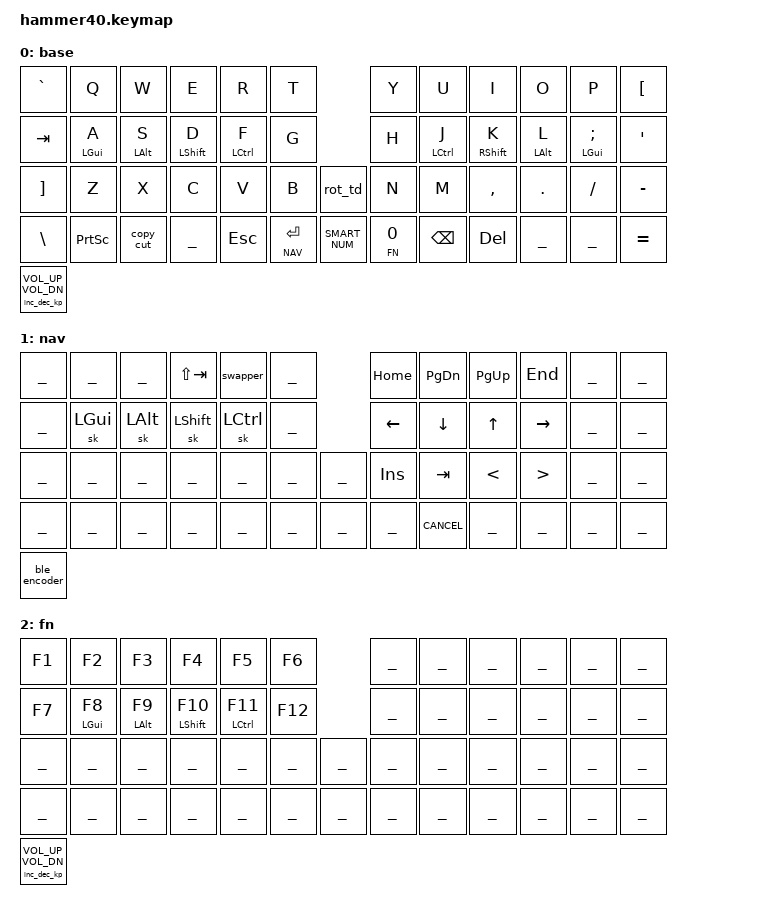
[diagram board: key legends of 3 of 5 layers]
/*
 * Copyright (c) 2020 The ZMK Contributors
 *
 * SPDX-License-Identifier: MIT
 */

#include <behaviors.dtsi>
#include <dt-bindings/zmk/keys.h>
#include <dt-bindings/zmk/bt.h>
#include <dt-bindings/zmk/outputs.h>

#include "hammer40_keylabels.h"
#include "zmk-helpers/helper.h"
#include "zmk-helpers/unicode-chars/currency.dtsi"

/* Layers */
#define DEF 0
#define NAV 1
#define FN 2
#define NUM 3
#define SYS 4

#include "mouse.dtsi"
#include "combos.dtsi"
#include "behave.dtsi"

/* Custom behaviors */

/ {
    behaviors {
        ble_encoder: ble_encoder {
            compatible = "zmk,behavior-sensor-rotate";
            #sensor-binding-cells = <0>;
            bindings = <&bt BT_NXT>, <&bt BT_PRV>;
        };
    };
};

// tap: play/pause | double-tap: media next | triple-tap: media previous
ZMK_TAP_DANCE(rot_td,
    tapping-term-ms = <250>;
    bindings = <&kp C_PP>, <&kp C_NEXT>, <&kp C_PREV>;
)


/* Keymap */

ZMK_CONDITIONAL_LAYER(sys, FN NUM, SYS)  // FN + NUM --> SYS

ZMK_LAYER(base,
//╭─────────────┬─────────────┬─────────────┬─────────────┬─────────────┬─────────────╮             ╭─────────────┬─────────────┬─────────────┬─────────────┬─────────────┬─────────────╮
    &kp GRAVE     &kp Q         &kp W         &kp E         &kp R         &kp T                       &kp Y         &kp U         &kp I         &kp O         &kp P           &kp LBKT
//├─────────────┼─────────────┼─────────────┼─────────────┼─────────────┼─────────────┤             ├─────────────┼─────────────┼─────────────┼─────────────┼─────────────┼─────────────┤
    &kp TAB       &hml LGUI A   &hml LALT S   &hml LSHFT D  &hml LCTRL F  &kp G                       &kp H         &hmr LCTRL J  &hmr RSHFT K  &hmr LALT L   &hmr LGUI SEMI  &kp APOS
//├─────────────┼─────────────┼─────────────┼─────────────┼─────────────┼─────────────┤ ╭─────────╮ ├─────────────┼─────────────┼─────────────┼─────────────┼─────────────┼─────────────┤
    &kp RBKT      &kp Z         &kp X         &kp C         &kp V         &kp B          &rot_td      &kp N         &kp M         &kp COMMA     &kp DOT       &kp FSLH        &kp MINUS
//├─────────────┼─────────────┼─────────────┼─────────────┼─────────────┼─────────────┼─────────────┼─────────────┼─────────────┼─────────────┼─────────────┼─────────────┼─────────────┤
    &kp BSLH      &kp PSCRN     &copy_cut     ___           &kp ESC       &lt NAV ENTER  SMART_NUM    &lt_spc FN 0  &kp BSPC      &kp DEL       ___           ___             &kp EQUAL
//╰─────────────┴─────────────┴─────────────┴─────────────┴─────────────┴─────────────┴─────────────┴─────────────┴─────────────┴─────────────┴─────────────┴─────────────┴─────────────╯ 
    , &inc_dec_kp C_VOL_UP C_VOL_DN
)

ZMK_LAYER(nav,
//╭─────────────┬─────────────┬─────────────┬─────────────┬─────────────┬─────────────╮             ╭─────────────┬─────────────┬─────────────┬─────────────┬─────────────┬─────────────╮
    ___           ___           ___           &kp LS(TAB)   &swapper      ___                         &kp HOME      &kp PG_DN     &kp PG_UP     &kp END       ___           ___
//├─────────────┼─────────────┼─────────────┼─────────────┼─────────────┼─────────────┤             ├─────────────┼─────────────┼─────────────┼─────────────┼─────────────┼─────────────┤
    ___           &sk LGUI      &sk LALT      &sk LSHFT     &sk LCTRL     ___                         &kp LEFT      &kp DOWN      &kp UP        &kp RIGHT     ___           ___
//├─────────────┼─────────────┼─────────────┼─────────────┼─────────────┼─────────────┤ ╭─────────╮ ├─────────────┼─────────────┼─────────────┼─────────────┼─────────────┼─────────────┤
    ___           ___           ___           ___           ___           ___               ___       &kp INS       &kp TAB       &kp LT        &kp GT        ___           ___
//├─────────────┼─────────────┼─────────────┼─────────────┼─────────────┼─────────────┼─────────────┼─────────────┼─────────────┼─────────────┼─────────────┼─────────────┼─────────────┤
    ___           ___           ___           ___           ___           ___               ___       ___           CANCEL        ___           ___           ___           ___
//╰─────────────┴─────────────┴─────────────┴─────────────┴─────────────┴─────────────┴─────────────┴─────────────┴─────────────┴─────────────┴─────────────┴─────────────┴─────────────╯ 
    , &ble_encoder
)

ZMK_LAYER(fn,
//╭─────────────┬─────────────┬─────────────┬─────────────┬─────────────┬─────────────╮             ╭─────────────┬─────────────┬─────────────┬─────────────┬─────────────┬─────────────╮
    &kp F1        &kp F2        &kp F3        &kp F4         &kp F5         &kp F6                    ___           ___           ___           ___           ___           ___
//├─────────────┼─────────────┼─────────────┼─────────────┼─────────────┼─────────────┤             ├─────────────┼─────────────┼─────────────┼─────────────┼─────────────┼─────────────┤
    &kp F7        &hml LGUI F8  &hml LALT F9  &hml LSHFT F10 &hml LCTRL F11 &kp F12                   ___           ___           ___           ___           ___           ___   
//├─────────────┼─────────────┼─────────────┼─────────────┼─────────────┼─────────────┤ ╭─────────╮ ├─────────────┼─────────────┼─────────────┼─────────────┼─────────────┼─────────────┤
    ___           ___           ___           ___            ___            ___             ___       ___           ___           ___           ___           ___           ___   
//├─────────────┼─────────────┼─────────────┼─────────────┼─────────────┼─────────────┼─────────────┼─────────────┼─────────────┼─────────────┼─────────────┼─────────────┼─────────────┤
    ___           ___           ___           ___            ___            ___             ___       ___           ___           ___           ___           ___           ___
//╰─────────────┴─────────────┴─────────────┴─────────────┴─────────────┴─────────────┴─────────────┴─────────────┴─────────────┴─────────────┴─────────────┴─────────────┴─────────────╯ 
    , &inc_dec_kp C_VOL_UP C_VOL_DN
)

ZMK_LAYER(num,
//╭─────────────┬─────────────┬─────────────┬─────────────┬─────────────┬─────────────╮             ╭─────────────┬─────────────┬─────────────┬─────────────┬─────────────┬─────────────╮
    ___       &curr_indian_rupee &kp N7        &kp N8        &kp N9        ___                         ___           &kp N9        &kp N8        &kp N7       &curr_indian_rupee  ___
//├─────────────┼─────────────┼─────────────┼─────────────┼─────────────┼─────────────┤             ├─────────────┼─────────────┼─────────────┼─────────────┼─────────────┼─────────────┤
    ___           &hml LGUI N0   &hml LALT N4  &hml LSHFT N5 &hml LCTRL N6 ___                         ___           &hml LCTRL N6 &hml LSHFT N5 &hml LALT N4 &hml LGUI N0        ___
//├─────────────┼─────────────┼─────────────┼─────────────┼─────────────┼─────────────┤ ╭─────────╮ ├─────────────┼─────────────┼─────────────┼─────────────┼─────────────┼─────────────┤
    ___           ___            &kp N1        &kp N2        &kp N3        ___              ___       ___           &kp N3        &kp N2        &kp N1        ___                 ___
//├─────────────┼─────────────┼─────────────┼─────────────┼─────────────┼─────────────┼─────────────┼─────────────┼─────────────┼─────────────┼─────────────┼─────────────┼─────────────┤
    ___           ___           ___           ___           ___            ___              ___       ___           ___           ___           ___           ___                 ___
//╰─────────────┴─────────────┴─────────────┴─────────────┴─────────────┴─────────────┴─────────────┴─────────────┴─────────────┴─────────────┴─────────────┴─────────────┴─────────────╯ 
)

ZMK_LAYER(sys,
//╭─────────────┬─────────────┬─────────────┬─────────────┬─────────────┬─────────────╮             ╭─────────────┬─────────────┬─────────────┬─────────────┬─────────────┬─────────────╮
    BLE_C(0)      BLE_C(1)      BLE_C(2)      BLE_C(3)      BLE_C(4)      &bt BT_CLR                  &bt BT_CLR_ALL BLE_D(4)     BLE_D(3)      BLE_D(2)      BLE_D(1)      BLE_D(0)
//├─────────────┼─────────────┼─────────────┼─────────────┼─────────────┼─────────────┤             ├─────────────┼─────────────┼─────────────┼─────────────┼─────────────┼─────────────┤
    ___           ___           ___           ___           &soft_off     &bootloader                 &bootloader    &soft_off    ___           ___
//├─────────────┼─────────────┼─────────────┼─────────────┼─────────────┼─────────────┤ ╭─────────╮ ├─────────────┼─────────────┼─────────────┼─────────────┼─────────────┼─────────────┤
    ___           ___           ___           ___           ___           &sys_reset        ___       &sys_reset     ___          ___           ___           ___           ___
//├─────────────┼─────────────┼─────────────┼─────────────┼─────────────┼─────────────┼─────────────┼─────────────┼─────────────┼─────────────┼─────────────┼─────────────┼─────────────┤
    &out OUT_BLE  &out OUT_USB  ___           ___           ___           ___               ___       ___            ___          ___           ___           &out OUT_USB  &out OUT_BLE
//╰─────────────┴─────────────┴─────────────┴─────────────┴─────────────┴─────────────┴─────────────┴─────────────┴─────────────┴─────────────┴─────────────┴─────────────┴─────────────╯ 
    , &ble_encoder
)
